# STM32F101_iown register map
Vendor: iown-homecontrol; Series: CM3; File version: 1.3
CPU: CM3 r1p1, little endian, no MPU, no FPU, VTOR, 4 interrupt priority bits
Registers are 32-bit, read-write, reset 0x0 unless marked. A register's access mark holds for its fields unless they carry their own. Offsets are from the block's base; [hi:lo] are bit positions; {n}, {i} and the like mark numbered series; 'fields as' and 'values as' point back to an identical list.

## AFIO — Alternate function I/O
Base 0x40010000
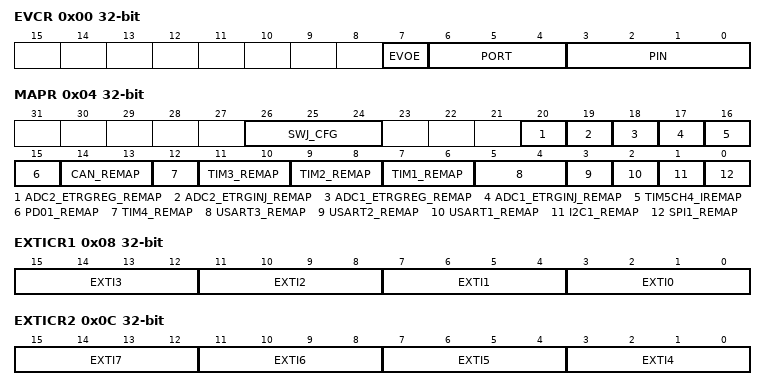
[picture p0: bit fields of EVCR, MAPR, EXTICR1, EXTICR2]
0x00 EVCR — Event Control Register (AFIO_EVCR)
  [7] EVOE — Event Output Enable
  [6:4] PORT — Port selection
  [3:0] PIN — Pin selection
0x04 MAPR — AF remap and debug I/O configuration register (AFIO_MAPR)
  [26:24] SWJ_CFG wo — Serial wire JTAG configuration
  [20] ADC2_ETRGREG_REMAP — ADC 2 external trigger regular conversion remapping
  [19] ADC2_ETRGINJ_REMAP — ADC 2 external trigger injected conversion remapping
  [18] ADC1_ETRGREG_REMAP — ADC 1 external trigger regular conversion remapping
  [17] ADC1_ETRGINJ_REMAP — ADC 1 External trigger injected conversion remapping
  [16] TIM5CH4_IREMAP — Set and cleared by software
  [15] PD01_REMAP — Port D0/Port D1 mapping on OSCIN/OSCOUT
  [14:13] CAN_REMAP — CAN1 remapping
  [12] TIM4_REMAP — TIM4 remapping
  [11:10] TIM3_REMAP — TIM3 remapping
  [9:8] TIM2_REMAP — TIM2 remapping
  [7:6] TIM1_REMAP — TIM1 remapping
  [5:4] USART3_REMAP — USART3 remapping
  [3] USART2_REMAP — USART2 remapping
  [2] USART1_REMAP — USART1 remapping
  [1] I2C1_REMAP — I2C1 remapping
  [0] SPI1_REMAP — SPI1 remapping
0x08 EXTICR1 — External interrupt configuration register 1 (AFIO_EXTICR1)
  [4n+3:4n] EXTI{n} (n=0..3) — EXTI{n} configuration
0x0C EXTICR2 — External interrupt configuration register 2 (AFIO_EXTICR2)
  [4n-13:4n-16] EXTI{n} (n=4..7) — EXTI{n} configuration
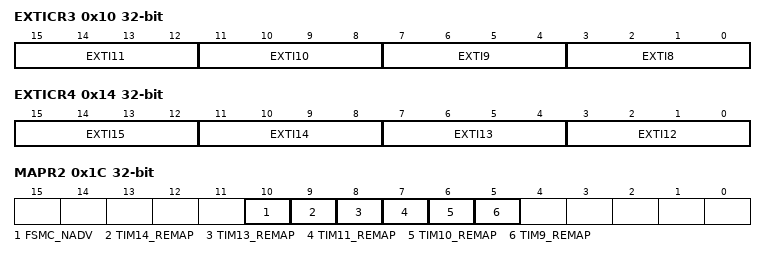
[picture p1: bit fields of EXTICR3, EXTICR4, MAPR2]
0x10 EXTICR3 — External interrupt configuration register 3 (AFIO_EXTICR3)
  [4n-29:4n-32] EXTI{n} (n=8..11) — EXTI{n} configuration
0x14 EXTICR4 — External interrupt configuration register 4 (AFIO_EXTICR4)
  [4n-45:4n-48] EXTI{n} (n=12..15) — EXTI{n} configuration
0x1C MAPR2 — AF remap and debug I/O configuration register
  [10] FSMC_NADV — NADV connect/disconnect
  [9] TIM14_REMAP — TIM14 remapping
  [8] TIM13_REMAP — TIM13 remapping
  [7] TIM11_REMAP — TIM11 remapping
  [6] TIM10_REMAP — TIM10 remapping
  [5] TIM9_REMAP — TIM9 remapping

## EXTI
Base 0x40010400
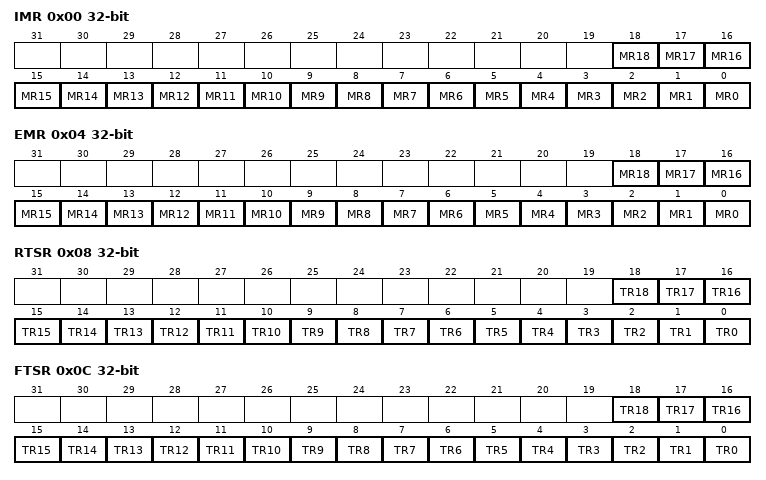
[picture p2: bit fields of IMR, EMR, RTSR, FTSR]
0x00 IMR — Interrupt mask register (EXTI_IMR)
  [n] MR{n} (n=1..18) — Interrupt Mask on line {n}
  [0] MR0 — Interrupt Mask on line 0
    0=Masked (Interrupt request line is masked); 1=Unmasked (Interrupt request line is unmasked)
0x04 EMR — Event mask register (EXTI_EMR)
  [n] MR{n} (n=1..18) — Event Mask on line {n}
  [0] MR0 — Event Mask on line 0
    values as IMR.MR0
0x08 RTSR — Rising Trigger selection register (EXTI_RTSR)
  [n] TR{n} (n=1..18) — Rising trigger event configuration of line {n}
  [0] TR0 — Rising trigger event configuration of line 0
    0=Disabled (Rising edge trigger is disabled); 1=Enabled (Rising edge trigger is enabled)
0x0C FTSR — Falling Trigger selection register (EXTI_FTSR)
  [n] TR{n} (n=1..18) — Falling trigger event configuration of line {n}
  [0] TR0 — Falling trigger event configuration of line 0
    0=Disabled (Falling edge trigger is disabled); 1=Enabled (Falling edge trigger is enabled)
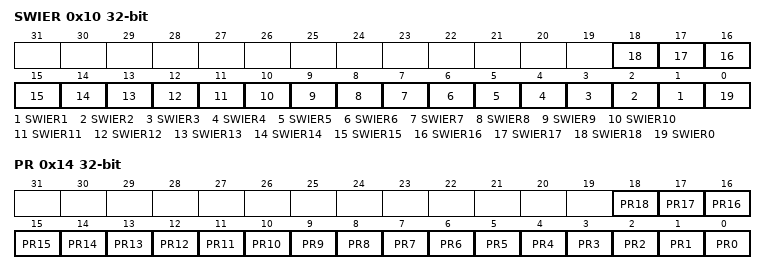
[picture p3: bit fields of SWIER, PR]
0x10 SWIER — Software interrupt event register (EXTI_SWIER)
  [n] SWIER{n} (n=1..18) — Software Interrupt on line {n}
  [0] SWIER0 — Software Interrupt on line 0
    on write: 1=Pend (Generates an interrupt request)
0x14 PR — Pending register (EXTI_PR)
  [all] fields
    on read: 0=NotPending (No trigger request occurred); 1=Pending (Selected trigger request occurred) | on write: 1=Clears pending bit
  [n] PR{n} write-1-clears (n=0..18) — Pending bit {n}

## DMA1 — DMA controller
Base 0x40020000
Same registers: DMA2 0x40020400
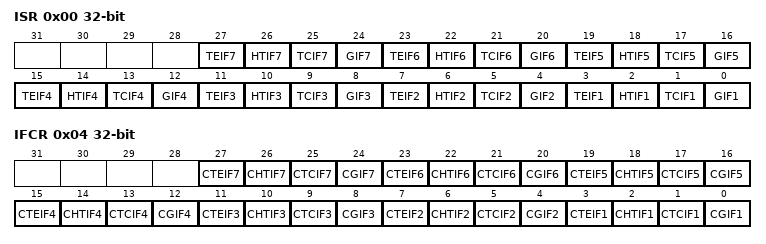
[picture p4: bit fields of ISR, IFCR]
0x00 ISR ro — DMA interrupt status register (DMA_ISR)
  [4n-1] TEIF{n} (n=2..7) — Channel {n} Transfer Error flag
  [4n-2] HTIF{n} (n=2..7) — Channel {n} Half Transfer Complete flag
  [4n-3] TCIF{n} (n=2..7) — Channel {n} Transfer Complete flag
  [4n-4] GIF{n} (n=2..7) — Channel {n} Global interrupt flag
  [3] TEIF1 — Channel 1 Transfer Error flag
    on read: 0=NoError (No transfer error); 1=Error (A transfer error has occured)
  [2] HTIF1 — Channel 1 Half Transfer Complete flag
    on read: 0=NotHalf (No half transfer event); 1=Half (A half transfer event has occured)
  [1] TCIF1 — Channel 1 Transfer Complete flag
    on read: 0=NotComplete (No transfer complete event); 1=Complete (A transfer complete event has occured)
  [0] GIF1 — Channel 1 Global interrupt flag
    on read: 0=NoEvent (No transfer error, half event, complete event); 1=Event (A transfer error, half event or complete event has occured)
0x04 IFCR wo — DMA interrupt flag clear register (DMA_IFCR)
  [4n-1] CTEIF{n} (n=2..7) — Channel {n} Transfer Error clear
  [4n-2] CHTIF{n} (n=2..7) — Channel {n} Half Transfer clear
  [4n-3] CTCIF{n} (n=2..7) — Channel {n} Transfer Complete clear
  [4n-4] CGIF{n} (n=2..7) — Channel {n} Global interrupt clear
  [3] CTEIF1 — Channel 1 Transfer Error clear
    on write: 1=Clears the TEIF flag in the ISR register
  [2] CHTIF1 — Channel 1 Half Transfer clear
    on write: 1=Clears the HTIF flag in the ISR register
  [1] CTCIF1 — Channel 1 Transfer Complete clear
    on write: 1=Clears the TCIF flag in the ISR register
  [0] CGIF1 — Channel 1 Global interrupt clear
    on write: 1=Clears the GIF, TEIF, HTIF, TCIF flags in the ISR register
